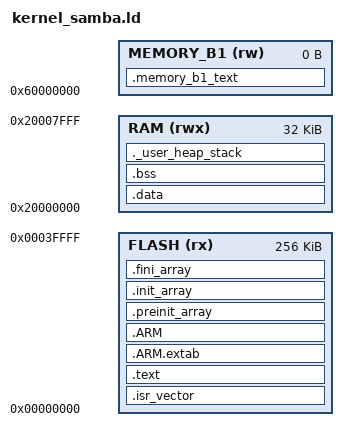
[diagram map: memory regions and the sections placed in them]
/******************************************************************************
 *
 * Linker configuration file for hello.
 *
 * Copyright (c) 2012 Texas Instruments Incorporated.  All rights reserved.
 * Software License Agreement
 * 
 * Texas Instruments (TI) is supplying this software for use solely and
 * exclusively on TI's microcontroller products. The software is owned by
 * TI and/or its suppliers, and is protected under applicable copyright
 * laws. You may not combine this software with "viral" open-source
 * software in order to form a larger program.
 * 
 * THIS SOFTWARE IS PROVIDED "AS IS" AND WITH ALL FAULTS.
 * NO WARRANTIES, WHETHER EXPRESS, IMPLIED OR STATUTORY, INCLUDING, BUT
 * NOT LIMITED TO, IMPLIED WARRANTIES OF MERCHANTABILITY AND FITNESS FOR
 * A PARTICULAR PURPOSE APPLY TO THIS SOFTWARE. TI SHALL NOT, UNDER ANY
 * CIRCUMSTANCES, BE LIABLE FOR SPECIAL, INCIDENTAL, OR CONSEQUENTIAL
 * DAMAGES, FOR ANY REASON WHATSOEVER.
 * 
 * This is part of revision 9453 of the EK-LM4F120XL Firmware Package.
 *
 *****************************************************************************/
/* Entry Point */
ENTRY(ResetISR)

/* Highest address of the user mode stack */
_estack = 0x20008000;    /* end of 32K RAM on AHB bus*/


/* Generate a link error if heap and stack don't fit into RAM */
_Min_Heap_Size = 0;      /* required amount of heap  */
_Min_Stack_Size = 0x200; /* required amount of stack 200 */ 


MEMORY
{
    FLASH (rx) : ORIGIN = 0x00000000, LENGTH = 0x00040000
    RAM (rwx) : ORIGIN = 0x20000000, LENGTH = 0x00008000
    MEMORY_B1 (rw) : ORIGIN = 0x60000000 , LENGTH = 0x00000000
}

SECTIONS
{ 

  /* The startup code goes first into FLASH */
  .isr_vector :
  {
    . = ALIGN(4);
    KEEP(*(.isr_vector)) /* Startup code */
    . = ALIGN(4);
  } >FLASH

    .text :
    {
     /* _text = .; */
     . = ALIGN(4);
      *(.text)           /* .text sections (code) */
      *(.text*)          /* .text* sections (code) */
      *(.rodata)         /* .rodata sections (constants, strings, etc.) */
      *(.rodata*)        /* .rodata* sections (constants, strings, etc.) */
      *(.glue_7)         /* glue arm to thumb code */
      *(.glue_7t)        /* glue thumb to arm code */
   	  *(.eh_frame)
   	  
      KEEP (*(.init))
      KEEP (*(.fini))

      . = ALIGN(4);
      _etext = .;        /* define a global symbols at end of code */

    } > FLASH

   .ARM.extab   : { *(.ARM.extab* .gnu.linkonce.armextab.*) } >FLASH
    .ARM : {
    __exidx_start = .;
      *(.ARM.exidx*)
      __exidx_end = .;
    } >FLASH

/*  .ARM.attributes : { *(.ARM.attributes) } > FLASH */

  .preinit_array     :
  {
    PROVIDE_HIDDEN (__preinit_array_start = .);
    KEEP (*(.preinit_array*))
    PROVIDE_HIDDEN (__preinit_array_end = .);
  } >FLASH
  .init_array :
  {
    PROVIDE_HIDDEN (__init_array_start = .);
    KEEP (*(SORT(.init_array.*)))
    KEEP (*(.init_array*))
    PROVIDE_HIDDEN (__init_array_end = .);
  } >FLASH
  .fini_array :
  {
    PROVIDE_HIDDEN (__fini_array_start = .);
    KEEP (*(.fini_array*))
    KEEP (*(SORT(.fini_array.*)))
    PROVIDE_HIDDEN (__fini_array_end = .);
  } >FLASH

    _sidata = .;
    .data : AT( _sidata )
    {
        . = ALIGN(4);
        _sdata = .;
        *(vtable)
        *(.data)
        *(.data*)
        . = ALIGN(4);
        _edata = .;
    } > RAM

    .bss :
    {
       . = ALIGN(4);
        _sbss = .;
        __bss_start__ = _sbss;
        *(.bss)
        *(.bss*)
        *(COMMON)
        . = ALIGN(4);
        _ebss = .;
        __bss_end__ = _ebss;
    } > RAM

  /* User_heap_stack section, used to check that there is enough RAM left */
  ._user_heap_stack :
  {
	__system_stack_bottom__ = . ;
    __stack_bottom = .;
    . = ALIGN(4);
    PROVIDE ( end = . );
    PROVIDE ( _end = . );
    . = . + _Min_Heap_Size;
    . = . + _Min_Stack_Size;
    . = ALIGN(4);
    __stack_top = .;
	__system_stack_top__ = . ;
  } >RAM

  /* MEMORY_bank1 section, code must be located here explicitly            */
  /* Example: extern int foo(void) __attribute__ ((section (".mb1text"))); */
  .memory_b1_text :
  {
    *(.mb1text)        /* .mb1text sections (code) */
    *(.mb1text*)       /* .mb1text* sections (code)  */
    *(.mb1rodata)      /* read-only data (constants) */
    *(.mb1rodata*)
  } >MEMORY_B1


   /* Remove information from the standard libraries */  
  /DISCARD/ :
  {
    libc.a ( * )
    libm.a ( * )
    libgcc.a ( * )
  }
  
  .ARM.attributes 0 : { *(.ARM.attributes) }
}

